# STM32H7A3x register map
File version: 2.0
CPU: CM7 r0p1, little endian, MPU, FPU, 4 interrupt priority bits
Registers are 32-bit, read-write, reset 0x0 unless marked. A register's access mark holds for its fields unless they carry their own. Offsets are from the block's base; [hi:lo] are bit positions; {n}, {i} and the like mark numbered series.

## CRC — Cryptographic processor
Base 0x40023000
0x00 DR reset 0xFFFFFFFF — Data register
  [31:0] DR — Data Register
0x04 IDR — Independent Data register
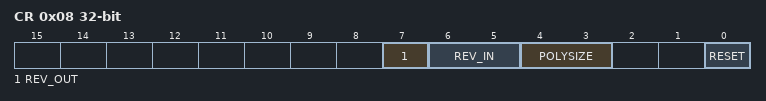
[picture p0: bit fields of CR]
0x08 CR access per field — Control register
  [7] REV_OUT rw — Reverse output data
  [6:5] REV_IN rw — Reverse input data
  [4:3] POLYSIZE rw — Polynomial size
  [0] RESET wo — RESET bit
0x0C INIT — Initial CRC value
  [31:0] CRC_INIT — Programmable initial CRC value
0x10 POL — CRC polynomial
  [31:0] POL — Programmable polynomial

## DBGMCU — Microcontroller Debug Unit
Base 0x5C001000
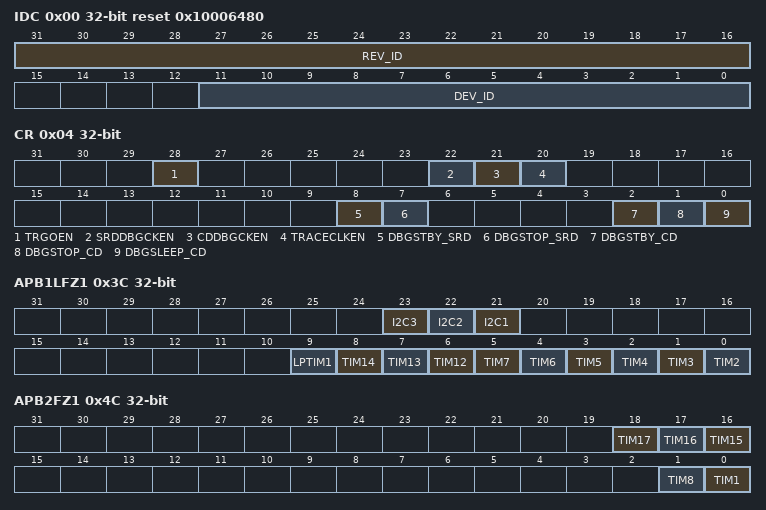
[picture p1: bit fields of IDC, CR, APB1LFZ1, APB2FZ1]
0x00 IDC ro reset 0x10006480 — DBGMCU Identity Code Register
  [31:16] REV_ID — Revision
  [11:0] DEV_ID — Device ID
0x04 CR — DBGMCU Configuration Register
  [28] TRGOEN — External trigger output enable
  [22] SRDDBGCKEN — SmartRun domain debug clock enable
  [21] CDDBGCKEN — CPU domain debug clock enable
  [20] TRACECLKEN — Trace port clock enable
  [8] DBGSTBY_SRD — debug in SmartRun domain Standby mode
  [7] DBGSTOP_SRD — debug in SmartRun domain Stop mode
  [2] DBGSTBY_CD — Allow D1 domain debug in Standby mode
  [1] DBGSTOP_CD — Allow D1 domain debug in Stop mode
  [0] DBGSLEEP_CD — Allow D1 domain debug in Sleep mode
0x34 APB3FZ1 — DBGMCU APB3 peripheral freeze register
  [6] WWDG — WWDG stop in debug
0x3C APB1LFZ1 — DBGMCU APB1L peripheral freeze register
  [23] I2C3 — I2C3 SMBUS timeout stop in debug
  [22] I2C2 — I2C2 SMBUS timeout stop in debug
  [21] I2C1 — I2C1 SMBUS timeout stop in debug
  [9] LPTIM1 — LPTIM1 stop in debug
  [8] TIM14 — TIM14 stop in debug
  [7] TIM13 — TIM13 stop in debug
  [6] TIM12 — TIM12 stop in debug
  [n-2] TIM{n} (n=2..7) — TIM{n} stop in debug
0x4C APB2FZ1 — DBGMCU APB2 peripheral freeze register
  [18] TIM17 — TIM17 stop in debug
  [17] TIM16 — TIM16 stop in debug
  [16] TIM15 — TIM15 stop in debug
  [1] TIM8 — TIM8 stop in debug
  [0] TIM1 — TIM1 stop in debug
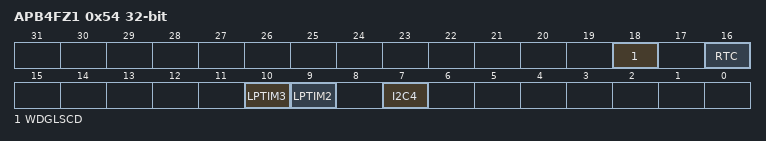
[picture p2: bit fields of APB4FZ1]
0x54 APB4FZ1 — DBGMCU APB4 peripheral freeze register
  [18] WDGLSCD — LS watchdog for CPU domain stop in debug
  [16] RTC — RTC stop in debug
  [10] LPTIM3 — LPTIM3 stop in debug
  [9] LPTIM2 — LPTIM2 stop in debug
  [7] I2C4 — I2C4 SMBUS timeout stop in debug

## DCMI — Digital camera interface
Base 0x48020000
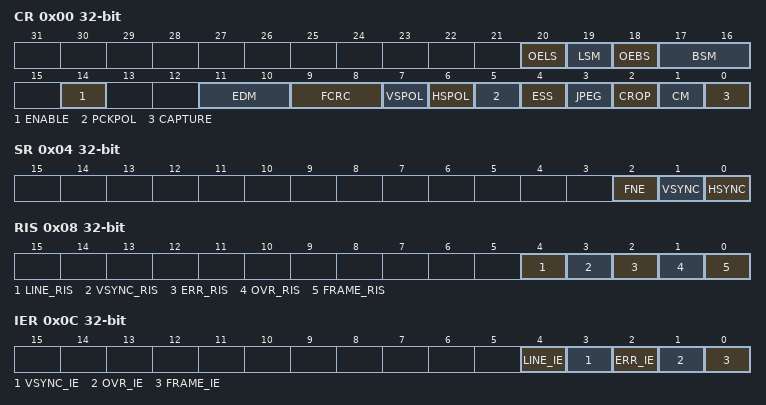
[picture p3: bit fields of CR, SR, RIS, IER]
0x00 CR — control register 1
  [20] OELS — Odd/Even Line Select (Line Select Start)
  [19] LSM — Line Select mode
  [18] OEBS — Odd/Even Byte Select (Byte Select Start)
  [17:16] BSM — Byte Select mode
  [14] ENABLE — DCMI enable
  [11:10] EDM — Extended data mode
  [9:8] FCRC — Frame capture rate control
  [7] VSPOL — Vertical synchronization polarity
  [6] HSPOL — Horizontal synchronization polarity
  [5] PCKPOL — Pixel clock polarity
  [4] ESS — Embedded synchronization select
  [3] JPEG — JPEG format
  [2] CROP — Crop feature
  [1] CM — Capture mode
  [0] CAPTURE — Capture enable
0x04 SR ro — status register
  [2] FNE — FIFO not empty
  [1] VSYNC
  [0] HSYNC
0x08 RIS ro — raw interrupt status register
  [4] LINE_RIS — Line raw interrupt status
  [3] VSYNC_RIS — VSYNC raw interrupt status
  [2] ERR_RIS — Synchronization error raw interrupt status
  [1] OVR_RIS — Overrun raw interrupt status
  [0] FRAME_RIS — Capture complete raw interrupt status
0x0C IER — interrupt enable register
  [4] LINE_IE — Line interrupt enable
  [3] VSYNC_IE — VSYNC interrupt enable
  [2] ERR_IE — Synchronization error interrupt enable
  [1] OVR_IE — Overrun interrupt enable
  [0] FRAME_IE — Capture complete interrupt enable
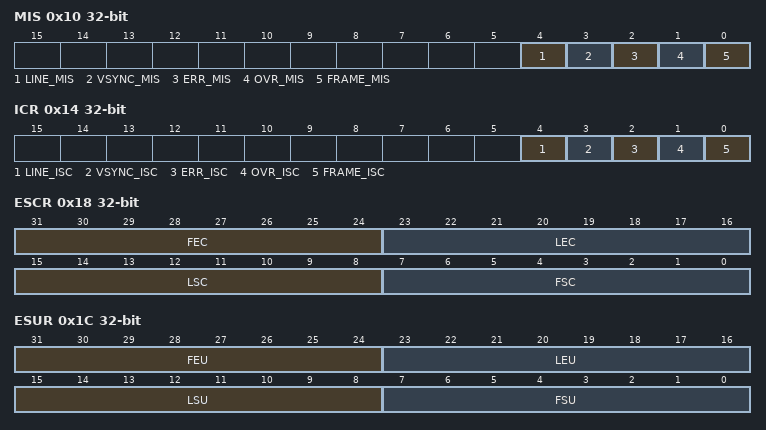
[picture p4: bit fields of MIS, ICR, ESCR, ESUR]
0x10 MIS ro — masked interrupt status register
  [4] LINE_MIS — Line masked interrupt status
  [3] VSYNC_MIS — VSYNC masked interrupt status
  [2] ERR_MIS — Synchronization error masked interrupt status
  [1] OVR_MIS — Overrun masked interrupt status
  [0] FRAME_MIS — Capture complete masked interrupt status
0x14 ICR wo — interrupt clear register
  [4] LINE_ISC — line interrupt status clear
  [3] VSYNC_ISC — Vertical synch interrupt status clear
  [2] ERR_ISC — Synchronization error interrupt status clear
  [1] OVR_ISC — Overrun interrupt status clear
  [0] FRAME_ISC — Capture complete interrupt status clear
0x18 ESCR — embedded synchronization code register
  [31:24] FEC — Frame end delimiter code
  [23:16] LEC — Line end delimiter code
  [15:8] LSC — Line start delimiter code
  [7:0] FSC — Frame start delimiter code
0x1C ESUR — embedded synchronization unmask register
  [31:24] FEU — Frame end delimiter unmask
  [23:16] LEU — Line end delimiter unmask
  [15:8] LSU — Line start delimiter unmask
  [7:0] FSU — Frame start delimiter unmask
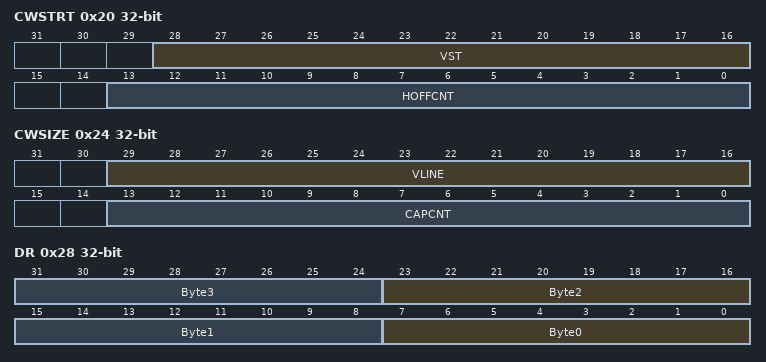
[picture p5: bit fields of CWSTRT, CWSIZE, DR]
0x20 CWSTRT — crop window start
  [28:16] VST — Vertical start line count
  [13:0] HOFFCNT — Horizontal offset count
0x24 CWSIZE — crop window size
  [29:16] VLINE — Vertical line count
  [13:0] CAPCNT — Capture count
0x28 DR ro — data register
  [8n+7:8n] Byte{n} (n=0..3) — Data byte {n}

## Notices in the file
Copyright (c) 2020 STMicroelectronics.
SPDX-License-Identifier: Apache-2.0
Licensed under the Apache License, Version 2.0 (the "License");
you may not use this file except in compliance with the License.
You may obtain a copy of the License at
http://www.apache.org/licenses/LICENSE-2.0
Unless required by applicable law or agreed to in writing, software
distributed under the License is distributed on an "AS IS" BASIS,
WITHOUT WARRANTIES OR CONDITIONS OF ANY KIND, either express or implied.
See the License for the specific language governing permissions and
limitations under the License.
